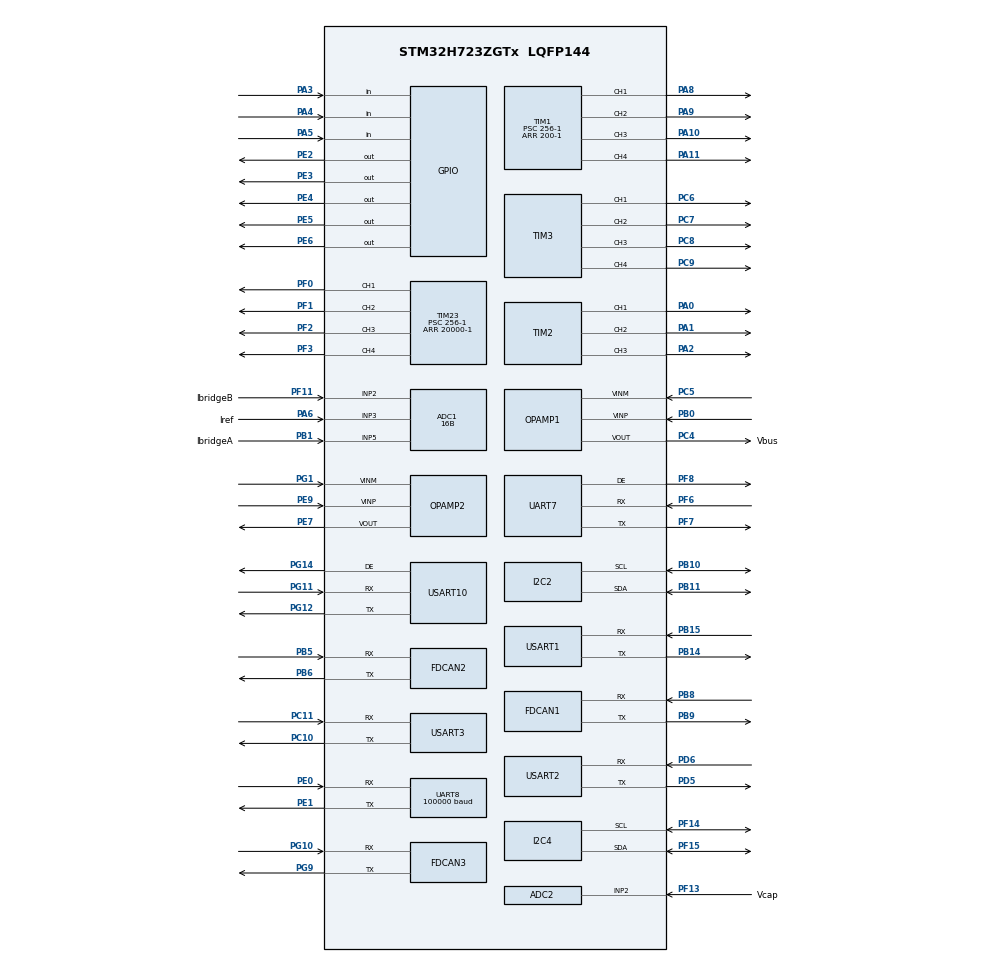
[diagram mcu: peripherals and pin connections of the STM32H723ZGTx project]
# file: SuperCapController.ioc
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ADC1.Channel-0\#ChannelRegularConversion=ADC_CHANNEL_4
ADC1.Channel-1\#ChannelRegularConversion=ADC_CHANNEL_2
ADC1.Channel-2\#ChannelRegularConversion=ADC_CHANNEL_3
ADC1.Channel-3\#ChannelRegularConversion=ADC_CHANNEL_5
ADC1.ClockPrescaler=ADC_CLOCK_ASYNC_DIV128
ADC1.ContinuousConvMode=ENABLE
ADC1.ConversionDataManagement=ADC_CONVERSIONDATA_DMA_CIRCULAR
ADC1.EOCSelection=ADC_EOC_SINGLE_CONV
ADC1.NbrOfConversion=4
ADC1.NbrOfConversionFlag=1
ADC1.OffsetNumber-0\#ChannelRegularConversion=ADC_OFFSET_NONE
ADC1.OffsetNumber-1\#ChannelRegularConversion=ADC_OFFSET_NONE
ADC1.OffsetNumber-2\#ChannelRegularConversion=ADC_OFFSET_NONE
ADC1.OffsetNumber-3\#ChannelRegularConversion=ADC_OFFSET_NONE
ADC1.OffsetSignedSaturation-0\#ChannelRegularConversion=DISABLE
ADC1.OffsetSignedSaturation-1\#ChannelRegularConversion=DISABLE
ADC1.OffsetSignedSaturation-2\#ChannelRegularConversion=DISABLE
ADC1.OffsetSignedSaturation-3\#ChannelRegularConversion=DISABLE
ADC1.Rank-0\#ChannelRegularConversion=1
ADC1.Rank-1\#ChannelRegularConversion=2
ADC1.Rank-2\#ChannelRegularConversion=3
ADC1.Rank-3\#ChannelRegularConversion=4
ADC1.Resolution=ADC_RESOLUTION_16B
ADC1.SamplingTime-0\#ChannelRegularConversion=ADC_SAMPLETIME_32CYCLES_5
ADC1.SamplingTime-1\#ChannelRegularConversion=ADC_SAMPLETIME_32CYCLES_5
ADC1.SamplingTime-2\#ChannelRegularConversion=ADC_SAMPLETIME_32CYCLES_5
ADC1.SamplingTime-3\#ChannelRegularConversion=ADC_SAMPLETIME_32CYCLES_5
ADC1.master=1
ADC2.Channel-2\#ChannelRegularConversion=ADC_CHANNEL_2
ADC2.Channel-3\#ChannelRegularConversion=ADC_CHANNEL_2
ADC2.ClockPrescaler=ADC_CLOCK_ASYNC_DIV128
ADC2.ContinuousConvMode=ENABLE
ADC2.ConversionDataManagement=ADC_CONVERSIONDATA_DMA_CIRCULAR
ADC2.NbrOfConversion=2
ADC2.NbrOfConversionFlag=1
ADC2.OffsetNumber-2\#ChannelRegularConversion=ADC_OFFSET_NONE
ADC2.OffsetNumber-3\#ChannelRegularConversion=ADC_OFFSET_NONE
ADC2.OffsetSignedSaturation-2\#ChannelRegularConversion=DISABLE
ADC2.OffsetSignedSaturation-3\#ChannelRegularConversion=DISABLE
ADC2.Rank-2\#ChannelRegularConversion=1
ADC2.Rank-3\#ChannelRegularConversion=2
ADC2.Resolution=ADC_RESOLUTION_16B
ADC2.SamplingTime-2\#ChannelRegularConversion=ADC_SAMPLETIME_16CYCLES_5
ADC2.SamplingTime-3\#ChannelRegularConversion=ADC_SAMPLETIME_16CYCLES_5
CORTEX_M7.default_mode_Activation=0
Dma.ADC1.6.Direction=DMA_PERIPH_TO_MEMORY
Dma.ADC1.6.EventEnable=DISABLE
Dma.ADC1.6.FIFOMode=DMA_FIFOMODE_DISABLE
Dma.ADC1.6.Instance=DMA1_Stream6
Dma.ADC1.6.MemDataAlignment=DMA_MDATAALIGN_HALFWORD
Dma.ADC1.6.MemInc=DMA_MINC_ENABLE
Dma.ADC1.6.Mode=DMA_CIRCULAR
Dma.ADC1.6.PeriphDataAlignment=DMA_PDATAALIGN_HALFWORD
Dma.ADC1.6.PeriphInc=DMA_PINC_DISABLE
Dma.ADC1.6.Polarity=HAL_DMAMUX_REQ_GEN_RISING
Dma.ADC1.6.Priority=DMA_PRIORITY_LOW
Dma.ADC1.6.RequestNumber=1
Dma.ADC1.6.SignalID=NONE
Dma.ADC1.6.SyncEnable=DISABLE
Dma.ADC1.6.SyncPolarity=HAL_DMAMUX_SYNC_NO_EVENT
Dma.ADC1.6.SyncRequestNumber=1
Dma.ADC1.6.SyncSignalID=NONE
Dma.ADC2.7.Direction=DMA_PERIPH_TO_MEMORY
Dma.ADC2.7.EventEnable=DISABLE
Dma.ADC2.7.FIFOMode=DMA_FIFOMODE_DISABLE
Dma.ADC2.7.Instance=DMA1_Stream7
Dma.ADC2.7.MemDataAlignment=DMA_MDATAALIGN_HALFWORD
Dma.ADC2.7.MemInc=DMA_MINC_ENABLE
Dma.ADC2.7.Mode=DMA_CIRCULAR
Dma.ADC2.7.PeriphDataAlignment=DMA_PDATAALIGN_HALFWORD
Dma.ADC2.7.PeriphInc=DMA_PINC_DISABLE
Dma.ADC2.7.Polarity=HAL_DMAMUX_REQ_GEN_RISING
Dma.ADC2.7.Priority=DMA_PRIORITY_LOW
Dma.ADC2.7.RequestNumber=1
Dma.ADC2.7.SignalID=NONE
Dma.ADC2.7.SyncEnable=DISABLE
Dma.ADC2.7.SyncPolarity=HAL_DMAMUX_SYNC_NO_EVENT
Dma.ADC2.7.SyncRequestNumber=1
Dma.ADC2.7.SyncSignalID=NONE
Dma.Request0=USART3_TX
Dma.Request1=USART2_TX
Dma.Request2=USART1_TX
Dma.Request3=USART1_RX
Dma.Request4=USART2_RX
Dma.Request5=USART3_RX
Dma.Request6=ADC1
Dma.Request7=ADC2
Dma.Request8=UART8_RX
Dma.UART8_RX.8.Direction=DMA_PERIPH_TO_MEMORY
Dma.UART8_RX.8.EventEnable=DISABLE
Dma.UART8_RX.8.FIFOMode=DMA_FIFOMODE_DISABLE
Dma.UART8_RX.8.Instance=DMA2_Stream0
Dma.UART8_RX.8.MemDataAlignment=DMA_MDATAALIGN_BYTE
Dma.UART8_RX.8.MemInc=DMA_MINC_ENABLE
Dma.UART8_RX.8.Mode=DMA_NORMAL
Dma.UART8_RX.8.PeriphDataAlignment=DMA_PDATAALIGN_BYTE
Dma.UART8_RX.8.PeriphInc=DMA_PINC_DISABLE
Dma.UART8_RX.8.Polarity=HAL_DMAMUX_REQ_GEN_RISING
Dma.UART8_RX.8.Priority=DMA_PRIORITY_VERY_HIGH
Dma.UART8_RX.8.RequestNumber=1
Dma.UART8_RX.8.SignalID=NONE
Dma.UART8_RX.8.SyncEnable=DISABLE
Dma.UART8_RX.8.SyncPolarity=HAL_DMAMUX_SYNC_NO_EVENT
Dma.UART8_RX.8.SyncRequestNumber=1
Dma.UART8_RX.8.SyncSignalID=NONE
Dma.USART1_RX.3.Direction=DMA_PERIPH_TO_MEMORY
Dma.USART1_RX.3.EventEnable=DISABLE
Dma.USART1_RX.3.FIFOMode=DMA_FIFOMODE_DISABLE
Dma.USART1_RX.3.Instance=DMA1_Stream3
Dma.USART1_RX.3.MemDataAlignment=DMA_MDATAALIGN_BYTE
Dma.USART1_RX.3.MemInc=DMA_MINC_ENABLE
Dma.USART1_RX.3.Mode=DMA_NORMAL
Dma.USART1_RX.3.PeriphDataAlignment=DMA_PDATAALIGN_BYTE
Dma.USART1_RX.3.PeriphInc=DMA_PINC_DISABLE
Dma.USART1_RX.3.Polarity=HAL_DMAMUX_REQ_GEN_RISING
Dma.USART1_RX.3.Priority=DMA_PRIORITY_VERY_HIGH
Dma.USART1_RX.3.RequestNumber=1
Dma.USART1_RX.3.SignalID=NONE
Dma.USART1_RX.3.SyncEnable=DISABLE
Dma.USART1_RX.3.SyncPolarity=HAL_DMAMUX_SYNC_NO_EVENT
Dma.USART1_RX.3.SyncRequestNumber=1
Dma.USART1_RX.3.SyncSignalID=NONE
Dma.USART1_TX.2.Direction=DMA_MEMORY_TO_PERIPH
Dma.USART1_TX.2.EventEnable=DISABLE
Dma.USART1_TX.2.FIFOMode=DMA_FIFOMODE_DISABLE
Dma.USART1_TX.2.Instance=DMA1_Stream2
Dma.USART1_TX.2.MemDataAlignment=DMA_MDATAALIGN_BYTE
Dma.USART1_TX.2.MemInc=DMA_MINC_ENABLE
Dma.USART1_TX.2.Mode=DMA_NORMAL
Dma.USART1_TX.2.PeriphDataAlignment=DMA_PDATAALIGN_BYTE
Dma.USART1_TX.2.PeriphInc=DMA_PINC_DISABLE
Dma.USART1_TX.2.Polarity=HAL_DMAMUX_REQ_GEN_RISING
Dma.USART1_TX.2.Priority=DMA_PRIORITY_VERY_HIGH
Dma.USART1_TX.2.RequestNumber=1
Dma.USART1_TX.2.SignalID=NONE
Dma.USART1_TX.2.SyncEnable=DISABLE
Dma.USART1_TX.2.SyncPolarity=HAL_DMAMUX_SYNC_NO_EVENT
Dma.USART1_TX.2.SyncRequestNumber=1
Dma.USART1_TX.2.SyncSignalID=NONE
Dma.USART2_RX.4.Direction=DMA_PERIPH_TO_MEMORY
Dma.USART2_RX.4.EventEnable=DISABLE
Dma.USART2_RX.4.FIFOMode=DMA_FIFOMODE_DISABLE
Dma.USART2_RX.4.Instance=DMA1_Stream4
Dma.USART2_RX.4.MemDataAlignment=DMA_MDATAALIGN_BYTE
Dma.USART2_RX.4.MemInc=DMA_MINC_ENABLE
Dma.USART2_RX.4.Mode=DMA_NORMAL
Dma.USART2_RX.4.PeriphDataAlignment=DMA_PDATAALIGN_BYTE
Dma.USART2_RX.4.PeriphInc=DMA_PINC_DISABLE
Dma.USART2_RX.4.Polarity=HAL_DMAMUX_REQ_GEN_RISING
Dma.USART2_RX.4.Priority=DMA_PRIORITY_VERY_HIGH
Dma.USART2_RX.4.RequestNumber=1
Dma.USART2_RX.4.SignalID=NONE
Dma.USART2_RX.4.SyncEnable=DISABLE
Dma.USART2_RX.4.SyncPolarity=HAL_DMAMUX_SYNC_NO_EVENT
Dma.USART2_RX.4.SyncRequestNumber=1
Dma.USART2_RX.4.SyncSignalID=NONE
Dma.USART2_TX.1.Direction=DMA_MEMORY_TO_PERIPH
Dma.USART2_TX.1.EventEnable=DISABLE
Dma.USART2_TX.1.FIFOMode=DMA_FIFOMODE_DISABLE
Dma.USART2_TX.1.Instance=DMA1_Stream1
Dma.USART2_TX.1.MemDataAlignment=DMA_MDATAALIGN_BYTE
Dma.USART2_TX.1.MemInc=DMA_MINC_ENABLE
Dma.USART2_TX.1.Mode=DMA_NORMAL
Dma.USART2_TX.1.PeriphDataAlignment=DMA_PDATAALIGN_BYTE
Dma.USART2_TX.1.PeriphInc=DMA_PINC_DISABLE
Dma.USART2_TX.1.Polarity=HAL_DMAMUX_REQ_GEN_RISING
Dma.USART2_TX.1.Priority=DMA_PRIORITY_VERY_HIGH
Dma.USART2_TX.1.RequestNumber=1
Dma.USART2_TX.1.SignalID=NONE
Dma.USART2_TX.1.SyncEnable=DISABLE
Dma.USART2_TX.1.SyncPolarity=HAL_DMAMUX_SYNC_NO_EVENT
Dma.USART2_TX.1.SyncRequestNumber=1
Dma.USART2_TX.1.SyncSignalID=NONE
Dma.USART3_RX.5.Direction=DMA_PERIPH_TO_MEMORY
Dma.USART3_RX.5.EventEnable=DISABLE
Dma.USART3_RX.5.FIFOMode=DMA_FIFOMODE_DISABLE
Dma.USART3_RX.5.Instance=DMA1_Stream5
Dma.USART3_RX.5.MemDataAlignment=DMA_MDATAALIGN_BYTE
Dma.USART3_RX.5.MemInc=DMA_MINC_ENABLE
Dma.USART3_RX.5.Mode=DMA_NORMAL
Dma.USART3_RX.5.PeriphDataAlignment=DMA_PDATAALIGN_BYTE
Dma.USART3_RX.5.PeriphInc=DMA_PINC_DISABLE
Dma.USART3_RX.5.Polarity=HAL_DMAMUX_REQ_GEN_RISING
Dma.USART3_RX.5.Priority=DMA_PRIORITY_VERY_HIGH
Dma.USART3_RX.5.RequestNumber=1
Dma.USART3_RX.5.SignalID=NONE
Dma.USART3_RX.5.SyncEnable=DISABLE
Dma.USART3_RX.5.SyncPolarity=HAL_DMAMUX_SYNC_NO_EVENT
Dma.USART3_RX.5.SyncRequestNumber=1
Dma.USART3_RX.5.SyncSignalID=NONE
Dma.USART3_TX.0.Direction=DMA_MEMORY_TO_PERIPH
Dma.USART3_TX.0.EventEnable=DISABLE
Dma.USART3_TX.0.FIFOMode=DMA_FIFOMODE_DISABLE
Dma.USART3_TX.0.Instance=DMA1_Stream0
Dma.USART3_TX.0.MemDataAlignment=DMA_MDATAALIGN_BYTE
Dma.USART3_TX.0.MemInc=DMA_MINC_ENABLE
Dma.USART3_TX.0.Mode=DMA_NORMAL
Dma.USART3_TX.0.PeriphDataAlignment=DMA_PDATAALIGN_BYTE
Dma.USART3_TX.0.PeriphInc=DMA_PINC_DISABLE
Dma.USART3_TX.0.Polarity=HAL_DMAMUX_REQ_GEN_RISING
Dma.USART3_TX.0.Priority=DMA_PRIORITY_VERY_HIGH
Dma.USART3_TX.0.RequestNumber=1
Dma.USART3_TX.0.SignalID=NONE
Dma.USART3_TX.0.SyncEnable=DISABLE
Dma.USART3_TX.0.SyncPolarity=HAL_DMAMUX_SYNC_NO_EVENT
Dma.USART3_TX.0.SyncRequestNumber=1
Dma.USART3_TX.0.SyncSignalID=NONE
FDCAN1.CalculateBaudRateNominal=1000000
FDCAN1.CalculateTimeBitNominal=1000
FDCAN1.CalculateTimeQuantumNominal=47.61904761904762
FDCAN1.DataPrescaler=6
FDCAN1.DataSyncJumpWidth=5
FDCAN1.DataTimeSeg1=15
FDCAN1.DataTimeSeg2=5
FDCAN1.ExtFiltersNbr=0
FDCAN1.Mode=FDCAN_MODE_NORMAL
FDCAN1.NominalPrescaler=6
FDCAN1.NominalSyncJumpWidth=5
FDCAN1.NominalTimeSeg1=15
FDCAN1.NominalTimeSeg2=5
FDCAN1.RxBuffersNbr=4
FDCAN1.RxFifo0ElmtsNbr=4
FDCAN1.RxFifo1ElmtsNbr=4
FDCAN1.StdFiltersNbr=1
FDCAN1.TxBuffersNbr=8
FDCAN1.TxEventsNbr=4
FDCAN1.TxFifoQueueElmtsNbr=8
FDCAN2.CalculateBaudRateNominal=1000000
FDCAN2.CalculateTimeBitNominal=1000
FDCAN2.CalculateTimeQuantumNominal=47.61904761904762
FDCAN2.DataPrescaler=6
FDCAN2.DataSyncJumpWidth=5
FDCAN2.DataTimeSeg1=15
FDCAN2.DataTimeSeg2=5
FDCAN2.MessageRAMOffset=0x406
FDCAN2.NominalPrescaler=6
FDCAN2.NominalSyncJumpWidth=5
FDCAN2.NominalTimeSeg1=15
FDCAN2.NominalTimeSeg2=5
FDCAN2.RxBuffersNbr=4
FDCAN2.RxFifo0ElmtsNbr=4
FDCAN2.RxFifo1ElmtsNbr=4
FDCAN2.StdFiltersNbr=1
FDCAN2.TxBuffersNbr=8
FDCAN2.TxEventsNbr=4
FDCAN2.TxFifoQueueElmtsNbr=8
FDCAN3.CalculateBaudRateNominal=1000000
FDCAN3.CalculateTimeBitNominal=1000
FDCAN3.CalculateTimeQuantumNominal=47.61904761904762
FDCAN3.DataPrescaler=6
FDCAN3.DataSyncJumpWidth=5
FDCAN3.DataTimeSeg1=15
FDCAN3.DataTimeSeg2=5
FDCAN3.MessageRAMOffset=0x812
FDCAN3.NominalPrescaler=6
FDCAN3.NominalSyncJumpWidth=5
FDCAN3.NominalTimeSeg1=15
FDCAN3.NominalTimeSeg2=5
FDCAN3.RxBuffersNbr=4
FDCAN3.RxFifo0ElmtsNbr=4
FDCAN3.RxFifo1ElmtsNbr=4
FDCAN3.StdFiltersNbr=1
FDCAN3.TxBuffersNbr=8
FDCAN3.TxEventsNbr=4
FDCAN3.TxFifoQueueElmtsNbr=8
FREERTOS.Tasks01=defaultTask,0,1024,StartDefaultTask,Default,NULL,Dynamic,NULL,NULL
I2C2.Timing=0x20A0C4DF
I2C4.Timing=0x20A0C4DF
Mcu.Family=STM32H7
Mcu.Name=STM32H723ZGTx
Mcu.Package=LQFP144
NVIC.DMA1_Stream0_IRQn=true\:5\:0\:false\:false\:true\:true\:false\:true\:true
NVIC.DMA1_Stream1_IRQn=true\:5\:0\:false\:false\:true\:true\:false\:true\:true
NVIC.DMA1_Stream2_IRQn=true\:5\:0\:false\:false\:true\:true\:false\:true\:true
NVIC.DMA1_Stream3_IRQn=true\:5\:0\:false\:false\:true\:true\:false\:true\:true
NVIC.DMA1_Stream4_IRQn=true\:5\:0\:false\:false\:true\:true\:false\:true\:true
NVIC.DMA1_Stream5_IRQn=true\:5\:0\:false\:false\:true\:true\:false\:true\:true
NVIC.DMA1_Stream6_IRQn=true\:5\:0\:false\:false\:true\:true\:false\:true\:true
NVIC.DMA1_Stream7_IRQn=true\:5\:0\:false\:false\:true\:true\:false\:true\:true
NVIC.DMA2_Stream0_IRQn=true\:5\:0\:false\:false\:true\:true\:false\:true\:true
NVIC.FDCAN1_IT0_IRQn=true\:5\:0\:false\:false\:true\:true\:true\:true\:true
NVIC.FDCAN1_IT1_IRQn=true\:5\:0\:false\:false\:true\:true\:true\:true\:true
NVIC.FDCAN2_IT0_IRQn=true\:5\:0\:false\:false\:true\:true\:true\:true\:true
NVIC.FDCAN2_IT1_IRQn=true\:5\:0\:false\:false\:true\:true\:true\:true\:true
NVIC.FDCAN3_IT0_IRQn=true\:5\:0\:false\:false\:true\:true\:true\:true\:true
NVIC.FDCAN3_IT1_IRQn=true\:5\:0\:false\:false\:true\:true\:true\:true\:true
NVIC.PriorityGroup=NVIC_PRIORITYGROUP_4
NVIC.UART8_IRQn=true\:5\:0\:false\:false\:true\:true\:true\:true\:true
NVIC.USART1_IRQn=true\:5\:0\:false\:false\:true\:true\:true\:true\:true
NVIC.USART2_IRQn=true\:5\:0\:false\:false\:true\:true\:true\:true\:true
NVIC.USART3_IRQn=true\:5\:0\:false\:false\:true\:true\:true\:true\:true
OPAMP1.PowerMode=OPAMP_POWERMODE_NORMAL
OPAMP2.PowerMode=OPAMP_POWERMODE_NORMAL
PA0.Signal=S_TIM2_CH1_ETR
PA1.Signal=S_TIM2_CH2
PA10.Signal=S_TIM1_CH3
PA11.Signal=S_TIM1_CH4
PA13(JTMS/SWDIO).Mode=Serial_Wire
PA13(JTMS/SWDIO).Signal=DEBUG_JTMS-SWDIO
PA14(JTCK/SWCLK).Mode=Serial_Wire
PA14(JTCK/SWCLK).Signal=DEBUG_JTCK-SWCLK
PA2.Signal=S_TIM2_CH3
PA3.Signal=GPIO_Input
PA4.Signal=GPIO_Input
PA5.Signal=GPIO_Input
PA6.GPIO_Label=Iref
PA6.Signal=ADCx_INP3
PA8.Signal=S_TIM1_CH1
PA9.Signal=S_TIM1_CH2
PB0.Mode=Standalone
PB0.Signal=OPAMP1_VINP
PB1.GPIO_Label=IbridgeA
PB1.Signal=ADCx_INP5
PB10.Mode=I2C
PB10.Signal=I2C2_SCL
PB11.Mode=I2C
PB11.Signal=I2C2_SDA
PB14.Mode=Asynchronous
PB14.Signal=USART1_TX
PB15.Mode=Asynchronous
PB15.Signal=USART1_RX
PB5.Mode=FDCAN_Activate
PB5.Signal=FDCAN2_RX
PB6.Mode=FDCAN_Activate
PB6.Signal=FDCAN2_TX
PB8.Mode=FDCAN_Activate
PB8.Signal=FDCAN1_RX
PB9.Mode=FDCAN_Activate
PB9.Signal=FDCAN1_TX
PC10.Mode=Asynchronous
PC10.Signal=USART3_TX
PC11.Mode=Asynchronous
PC11.Signal=USART3_RX
PC4.GPIO_Label=Vbus
PC4.Signal=SharedAnalog_PC4
PC5.Mode=Standalone
PC5.Signal=OPAMP1_VINM
PC6.Signal=S_TIM3_CH1
PC7.Signal=S_TIM3_CH2
PC8.Signal=S_TIM3_CH3
PC9.Signal=S_TIM3_CH4
PD5.Mode=Asynchronous
PD5.Signal=USART2_TX
PD6.Mode=Asynchronous
PD6.Signal=USART2_RX
PE0.Mode=Asynchronous
PE0.Signal=UART8_RX
PE1.Mode=Asynchronous
PE1.Signal=UART8_TX
PE2.GPIO_PuPd=GPIO_NOPULL
PE2.GPIO_Speed=GPIO_SPEED_FREQ_MEDIUM
PE2.Signal=GPIO_Output
PE3.GPIO_ModeDefaultOutputPP=GPIO_MODE_OUTPUT_PP
PE3.GPIO_PuPd=GPIO_NOPULL
PE3.GPIO_Speed=GPIO_SPEED_FREQ_MEDIUM
PE3.PinState=GPIO_PIN_RESET
PE3.Signal=GPIO_Output
PE4.GPIO_ModeDefaultOutputPP=GPIO_MODE_OUTPUT_PP
PE4.GPIO_PuPd=GPIO_NOPULL
PE4.GPIO_Speed=GPIO_SPEED_FREQ_MEDIUM
PE4.Signal=GPIO_Output
PE5.GPIO_ModeDefaultOutputPP=GPIO_MODE_OUTPUT_PP
PE5.GPIO_PuPd=GPIO_NOPULL
PE5.GPIO_Speed=GPIO_SPEED_FREQ_MEDIUM
PE5.Signal=GPIO_Output
PE6.GPIO_PuPd=GPIO_NOPULL
PE6.GPIO_Speed=GPIO_SPEED_FREQ_MEDIUM
PE6.Signal=GPIO_Output
PE7.Mode=Standalone
PE7.Signal=OPAMP2_VOUT
PE9.Mode=Standalone
PE9.Signal=OPAMP2_VINP
PF0.Mode=PWM Generation1 CH1
PF0.Signal=TIM23_CH1
PF1.Signal=S_TIM23_CH2
PF11.GPIO_Label=IbridgeB
PF11.Mode=IN2-Single-Ended
PF11.Signal=ADC1_INP2
PF13.GPIO_Label=Vcap
PF13.Mode=IN2-Single-Ended
PF13.Signal=ADC2_INP2
PF14.Mode=I2C
PF14.Signal=I2C4_SCL
PF15.Mode=I2C
PF15.Signal=I2C4_SDA
PF2.Signal=S_TIM23_CH3
PF3.Signal=S_TIM23_CH4
PF6.Mode=Asynchronous
PF6.Signal=UART7_RX
PF7.Mode=Asynchronous
PF7.Signal=UART7_TX
PF8.Mode=Hardware Flow Control (RS485)
PF8.Signal=UART7_DE
PG1.Mode=Standalone
PG1.Signal=OPAMP2_VINM
PG10.Mode=FDCAN_Activate
PG10.Signal=FDCAN3_RX
PG11.Mode=Asynchronous
PG11.Signal=USART10_RX
PG12.Mode=Asynchronous
PG12.Signal=USART10_TX
PG14.Mode=Hardware Flow Control (RS485)
PG14.Signal=USART10_DE
PG9.Mode=FDCAN_Activate
PG9.Signal=FDCAN3_TX
PH0-OSC_IN.Mode=HSE-External-Oscillator
PH0-OSC_IN.Signal=RCC_OSC_IN
PH1-OSC_OUT.Mode=HSE-External-Oscillator
PH1-OSC_OUT.Signal=RCC_OSC_OUT
ProjectManager.HeapSize=0x200
ProjectManager.StackSize=0x400
ProjectManager.TargetToolchain=STM32CubeIDE
RCC.ADCFreq_Value=126000000
RCC.APB1Freq_Value=128000000
RCC.APB2Freq_Value=128000000
RCC.APB3Freq_Value=128000000
RCC.APB4Freq_Value=128000000
RCC.CortexFreq_Value=256000000
RCC.D1PPRE=RCC_APB3_DIV2
RCC.D2PPRE1=RCC_APB1_DIV2
RCC.D2PPRE2=RCC_APB2_DIV2
RCC.D3PPRE=RCC_APB4_DIV2
RCC.DIVM1=1
RCC.DIVM2=1
RCC.DIVN1=64
RCC.DIVN2=21
RCC.DIVP1=3
RCC.DIVQ1=6
RCC.FDCANCLockSelection=RCC_FDCANCLKSOURCE_PLL2
RCC.HCLKFreq_Value=256000000
RCC.HSE_VALUE=12000000
RCC.PLL2FRACN=0
RCC.PLL2_VCI_Range-AdvancedSettings=RCC_PLL2VCIRANGE_0
RCC.PLL2_VCO_SEL-AdvancedSettings=RCC_PLL2VCOMEDIUM
RCC.PLL3FRACN=0
RCC.PLLFRACN=0
RCC.PLLSourceVirtual=RCC_PLLSOURCE_HSE
RCC.SYSCLKFreq_VALUE=256000000
RCC.SYSCLKSource=RCC_SYSCLKSOURCE_PLLCLK
RCC.USBFreq_Value=128000000
SH.ADCx_INP3.0=ADC1_INP3,IN3-Single-Ended
SH.ADCx_INP5.0=ADC1_INP5,IN5-Single-Ended
SH.S_TIM1_CH1.0=TIM1_CH1,PWM Generation1 CH1
SH.S_TIM1_CH2.0=TIM1_CH2,PWM Generation2 CH2
SH.S_TIM1_CH3.0=TIM1_CH3,PWM Generation3 CH3
SH.S_TIM1_CH4.0=TIM1_CH4,PWM Generation4 CH4
SH.S_TIM23_CH2.0=TIM23_CH2,PWM Generation2 CH2
SH.S_TIM23_CH3.0=TIM23_CH3,PWM Generation3 CH3
SH.S_TIM23_CH4.0=TIM23_CH4,PWM Generation4 CH4
SH.S_TIM2_CH1_ETR.0=TIM2_CH1,PWM Generation1 CH1
SH.S_TIM2_CH2.0=TIM2_CH2,PWM Generation2 CH2
SH.S_TIM2_CH3.0=TIM2_CH3,PWM Generation3 CH3
SH.S_TIM3_CH1.0=TIM3_CH1,PWM Generation1 CH1
SH.S_TIM3_CH2.0=TIM3_CH2,PWM Generation2 CH2
SH.S_TIM3_CH3.0=TIM3_CH3,PWM Generation3 CH3
SH.S_TIM3_CH4.0=TIM3_CH4,PWM Generation4 CH4
SH.SharedAnalog_PC4.0=ADC1_INP4
SH.SharedAnalog_PC4.1=OPAMP1_VOUT,Standalone
TIM1.AutoReloadPreload=TIM_AUTORELOAD_PRELOAD_ENABLE
TIM1.Channel-PWM\ Generation1\ CH1=TIM_CHANNEL_1
TIM1.Channel-PWM\ Generation2\ CH2=TIM_CHANNEL_2
TIM1.Channel-PWM\ Generation3\ CH3=TIM_CHANNEL_3
TIM1.Channel-PWM\ Generation4\ CH4=TIM_CHANNEL_4
TIM1.Period=200-1
TIM1.Prescaler=256-1
TIM1.Pulse-PWM\ Generation1\ CH1=100-1
TIM1.Pulse-PWM\ Generation2\ CH2=100-1
TIM1.Pulse-PWM\ Generation3\ CH3=100-1
TIM1.Pulse-PWM\ Generation4\ CH4=100-1
TIM2.Channel-PWM\ Generation1\ CH1=TIM_CHANNEL_1
TIM2.Channel-PWM\ Generation2\ CH2=TIM_CHANNEL_2
TIM2.Channel-PWM\ Generation3\ CH3=TIM_CHANNEL_3
TIM23.AutoReloadPreload=TIM_AUTORELOAD_PRELOAD_ENABLE
TIM23.Channel-PWM\ Generation1\ CH1=TIM_CHANNEL_1
TIM23.Channel-PWM\ Generation2\ CH2=TIM_CHANNEL_2
TIM23.Channel-PWM\ Generation3\ CH3=TIM_CHANNEL_3
TIM23.Channel-PWM\ Generation4\ CH4=TIM_CHANNEL_4
TIM23.Period=20000-1
TIM23.Prescaler=256-1
TIM23.Pulse-PWM\ Generation1\ CH1=1000-1
TIM23.Pulse-PWM\ Generation2\ CH2=1000-1
TIM23.Pulse-PWM\ Generation3\ CH3=1000-1
TIM23.Pulse-PWM\ Generation4\ CH4=1000-1
TIM3.Channel-PWM\ Generation1\ CH1=TIM_CHANNEL_1
TIM3.Channel-PWM\ Generation2\ CH2=TIM_CHANNEL_2
TIM3.Channel-PWM\ Generation3\ CH3=TIM_CHANNEL_3
TIM3.Channel-PWM\ Generation4\ CH4=TIM_CHANNEL_4
UART8.BaudRate=100000
UART8.Parity=PARITY_EVEN
UART8.StopBits=UART_STOPBITS_1
UART8.WordLength=WORDLENGTH_8B
USART1.VirtualMode-Asynchronous=VM_ASYNC
USART10.VirtualMode-Asynchronous=VM_ASYNC
USART10.VirtualMode-Hardware\ Flow\ Control\ (RS485)=VM_ASYNC
USART2.VirtualMode-Asynchronous=VM_ASYNC
USART3.VirtualMode-Asynchronous=VM_ASYNC
VP_ADC1_OPAMP1_OUT.Mode=IN4-OPAMP1-Single-Ended
VP_FREERTOS_VS_CMSIS_V1.Mode=CMSIS_V1
VP_MEMORYMAP_VS_MEMORYMAP.Mode=CurAppReg
VP_TIM1_VS_ClockSourceINT.Mode=Internal
VP_TIM23_VS_ClockSourceINT.Mode=Internal
board=custom

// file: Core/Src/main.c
/* USER CODE BEGIN Header */
/**
  ******************************************************************************
  * @file           : main.c
  * @brief          : Main program body
  ******************************************************************************
  * @attention
  *
  * Copyright (c) 2025 STMicroelectronics.
  * All rights reserved.
  *
  * This software is licensed under terms that can be found in the LICENSE file
  * in the root directory of this software component.
  * If no LICENSE file comes with this software, it is provided AS-IS.
  *
  ******************************************************************************
  */
/* USER CODE END Header */
#include "main.h"
#include "cmsis_os.h"

/* USER CODE BEGIN Includes */
#include "stdio.h"
#include "stdarg.h"
#include "string.h"
#include "UART.h"
#include "CAN_FD.h"
#include "cybergear.h"
#include "remote_control.h"
#include "stdlib.h"

/* USER CODE END Includes */

ADC_HandleTypeDef hadc1;
ADC_HandleTypeDef hadc2;
DMA_HandleTypeDef hdma_adc1;
DMA_HandleTypeDef hdma_adc2;

FDCAN_HandleTypeDef hfdcan1;
FDCAN_HandleTypeDef hfdcan2;
FDCAN_HandleTypeDef hfdcan3;

I2C_HandleTypeDef hi2c2;
I2C_HandleTypeDef hi2c4;

OPAMP_HandleTypeDef hopamp1;
OPAMP_HandleTypeDef hopamp2;

TIM_HandleTypeDef htim1;
TIM_HandleTypeDef htim2;
TIM_HandleTypeDef htim3;
TIM_HandleTypeDef htim23;

UART_HandleTypeDef huart7;
UART_HandleTypeDef huart8;
UART_HandleTypeDef huart1;
UART_HandleTypeDef huart2;
UART_HandleTypeDef huart3;
UART_HandleTypeDef huart10;
DMA_HandleTypeDef hdma_uart8_rx;
DMA_HandleTypeDef hdma_usart1_tx;
DMA_HandleTypeDef hdma_usart1_rx;
DMA_HandleTypeDef hdma_usart2_tx;
DMA_HandleTypeDef hdma_usart2_rx;
DMA_HandleTypeDef hdma_usart3_tx;
DMA_HandleTypeDef hdma_usart3_rx;

osThreadId defaultTaskHandle;
/* USER CODE BEGIN PV */
FDCAN_HandleTypeDef hfdcan1;
FDCAN_HandleTypeDef hfdcan2;
FDCAN_HandleTypeDef hfdcan3;

PID_preset_t chassisPreset = {3.6, 0, 0};  //0.8f, 0.025f, 0.95f   {1.6, 0.045, 0.10}; 32 0.4
PID_preset_t yawPresetCurrentRPM = {46, 10.0, 16.4};
PID_preset_t yawPresetVoltageRPM = {300, 0, 0};
PID_preset_t yawPresetCurrentPosition = {12, 1, 0.0};
PID_preset_t yawPresetVoltagePosition = {36, 0.3, 0.0};
PID_preset_t pitchPresetVoltagePosition = {70.0, 0.0, 421.0};
PID_preset_t indexerPreset = {1.1f, 0.02f, -2.4f};
PID_preset_t shooterPreset = {1.20f, 0.12f, 1.60f};
PID_preset_t powerPreset = {0, 0.000000000001, 0};
PID_preset_t flywheel = {12, 0, 0};
PID_preset_t customPreset = {0, 0, 0};

RC_ctrl_t local_rc_ctrl;

const int16_t maxValAllowed = 800;
/* USER CODE END PV */

void SystemClock_Config(void);
void PeriphCommonClock_Config(void);
static void MX_GPIO_Init(void);
static void MX_DMA_Init(void);
static void MX_ADC1_Init(void);
static void MX_ADC2_Init(void);
static void MX_FDCAN1_Init(void);
static void MX_FDCAN2_Init(void);
static void MX_FDCAN3_Init(void);
static void MX_I2C2_Init(void);
static void MX_I2C4_Init(void);
static void MX_OPAMP1_Init(void);
static void MX_OPAMP2_Init(void);
static void MX_TIM1_Init(void);
static void MX_TIM2_Init(void);
static void MX_TIM3_Init(void);
static void MX_TIM23_Init(void);
static void MX_UART7_Init(void);
static void MX_USART1_UART_Init(void);
static void MX_USART2_UART_Init(void);
static void MX_USART3_UART_Init(void);
static void MX_USART10_UART_Init(void);
static void MX_UART8_Init(void);
void StartDefaultTask(void const * argument);

int main(void)
{

  /* MCU Configuration--------------------------------------------------------*/

  /* Reset of all peripherals, Initializes the Flash interface and the Systick. */
  HAL_Init();

  /* Configure the system clock */
  SystemClock_Config();

  /* Configure the peripherals common clocks */
  PeriphCommonClock_Config();

  /* Initialize all configured peripherals */
  MX_GPIO_Init();
  MX_DMA_Init();
  MX_ADC1_Init();
  MX_ADC2_Init();
  MX_FDCAN1_Init();
  MX_FDCAN2_Init();
  MX_FDCAN3_Init();
  MX_I2C2_Init();
  MX_I2C4_Init();
  MX_OPAMP1_Init();
  MX_OPAMP2_Init();
  MX_TIM1_Init();
  MX_TIM2_Init();
  MX_TIM3_Init();
  MX_TIM23_Init();
  MX_UART7_Init();
  MX_USART1_UART_Init();
  MX_USART2_UART_Init();
  MX_USART3_UART_Init();
  MX_USART10_UART_Init();
  MX_UART8_Init();
  /* USER CODE BEGIN 2 */
  HAL_TIM_Base_Start(&htim1);
  HAL_TIM_PWM_Start(&htim1, TIM_CHANNEL_1);
  HAL_TIM_PWM_Start(&htim1, TIM_CHANNEL_2);
  HAL_TIM_PWM_Start(&htim1, TIM_CHANNEL_3);
  HAL_TIM_PWM_Start(&htim1, TIM_CHANNEL_4);

  HAL_TIM_Base_Start(&htim23);
  HAL_TIM_PWM_Start(&htim23, TIM_CHANNEL_1);
  HAL_TIM_PWM_Start(&htim23, TIM_CHANNEL_2);
  HAL_TIM_PWM_Start(&htim23, TIM_CHANNEL_3);
  HAL_TIM_PWM_Start(&htim23, TIM_CHANNEL_4);
  uint16_t constant = 1000;
  uint16_t count = 100;
  HAL_GPIO_WritePin(GPIOE, GPIO_PIN_2, 0);
  HAL_GPIO_WritePin(GPIOE, GPIO_PIN_3, 0);
  HAL_GPIO_WritePin(GPIOE, GPIO_PIN_4, 0);
  HAL_GPIO_WritePin(GPIOE, GPIO_PIN_5, 0);
  HAL_GPIO_WritePin(GPIOE, GPIO_PIN_6, 0);
  bsp_can_init();
  //usart_Init();
  uint8_t CAN_Data = 125;
  uint8_t CAN_State = -1;

  /* USER CODE END 2 */

  /* Create the thread(s) */
  /* definition and creation of defaultTask */
  osThreadDef(defaultTask, StartDefaultTask, osPriorityNormal, 0, 1024);
  defaultTaskHandle = osThreadCreate(osThread(defaultTask), NULL);

  /* Start scheduler */
  osKernelStart();

  /* We should never get here as control is now taken by the scheduler */

  /* Infinite loop */
  /* USER CODE BEGIN WHILE */
  while (1)
  {
	  __HAL_TIM_SetCompare(&htim1, TIM_CHANNEL_1, count);
	  __HAL_TIM_SetCompare(&htim1, TIM_CHANNEL_2, count);
	  __HAL_TIM_SetCompare(&htim1, TIM_CHANNEL_3, count);
	  __HAL_TIM_SetCompare(&htim1, TIM_CHANNEL_4, count);

	  __HAL_TIM_SetCompare(&htim23, TIM_CHANNEL_1, constant);
	  __HAL_TIM_SetCompare(&htim23, TIM_CHANNEL_2, constant);
	  __HAL_TIM_SetCompare(&htim23, TIM_CHANNEL_3, constant);
	  __HAL_TIM_SetCompare(&htim23, TIM_CHANNEL_4, constant);
	  //count++;
	  if(count > 100) {
		  count = 10;
	  }

	  //HAL_GPIO_WritePin(GPIOE, GPIO_PIN_2, 1);
	  //HAL_GPIO_WritePin(GPIOE, GPIO_PIN_3, 1);
	  //HAL_GPIO_WritePin(GPIOE, GPIO_PIN_4, 1);
	  //HAL_GPIO_WritePin(GPIOE, GPIO_PIN_5, 1);
	  //HAL_GPIO_WritePin(GPIOE, GPIO_PIN_6, 1);

	  //HAL_Delay(50);

	  HAL_GPIO_TogglePin(GPIOE, GPIO_PIN_2);
	  HAL_GPIO_TogglePin(GPIOE, GPIO_PIN_3);
	  HAL_GPIO_TogglePin(GPIOE, GPIO_PIN_4);
	  HAL_GPIO_TogglePin(GPIOE, GPIO_PIN_5);
	  //HAL_UART_Transmit(&huart1, "UART 1", 6, 100);
	  //HAL_UART_Transmit(&huart2, "UART 2", 6, 100);
	  //HAL_UART_Transmit(&huart3, "UART 3", 6, 100); //use this for debugging
	  //CAN_State = fdcanx_send_data(&hfdcan1, 0x01, &CAN_Data, 8);
	  //usart_printf("CAN_State=%d \r\n", CAN_State);

	  HAL_Delay(500);
	  //usart_printf("ABC\r\n",100);
    /* USER CODE END WHILE */

  }
}

void SystemClock_Config(void)
{
  RCC_OscInitTypeDef RCC_OscInitStruct = {0};
  RCC_ClkInitTypeDef RCC_ClkInitStruct = {0};

  /** Supply configuration update enable
  */
  HAL_PWREx_ConfigSupply(PWR_LDO_SUPPLY);

  /** Configure the main internal regulator output voltage
  */
  __HAL_PWR_VOLTAGESCALING_CONFIG(PWR_REGULATOR_VOLTAGE_SCALE0);

  while(!__HAL_PWR_GET_FLAG(PWR_FLAG_VOSRDY)) {}

  /** Initializes the RCC Oscillators according to the specified parameters
  * in the RCC_OscInitTypeDef structure.
  */
  RCC_OscInitStruct.OscillatorType = RCC_OSCILLATORTYPE_HSE;
  RCC_OscInitStruct.HSEState = RCC_HSE_ON;
  RCC_OscInitStruct.PLL.PLLState = RCC_PLL_ON;
  RCC_OscInitStruct.PLL.PLLSource = RCC_PLLSOURCE_HSE;
  RCC_OscInitStruct.PLL.PLLM = 1;
  RCC_OscInitStruct.PLL.PLLN = 64;
  RCC_OscInitStruct.PLL.PLLP = 3;
  RCC_OscInitStruct.PLL.PLLQ = 6;
  RCC_OscInitStruct.PLL.PLLR = 2;
  RCC_OscInitStruct.PLL.PLLRGE = RCC_PLL1VCIRANGE_3;
  RCC_OscInitStruct.PLL.PLLVCOSEL = RCC_PLL1VCOWIDE;
  RCC_OscInitStruct.PLL.PLLFRACN = 0;
  if (HAL_RCC_OscConfig(&RCC_OscInitStruct) != HAL_OK)
  {
    Error_Handler();
  }

  /** Initializes the CPU, AHB and APB buses clocks
  */
  RCC_ClkInitStruct.ClockType = RCC_CLOCKTYPE_HCLK|RCC_CLOCKTYPE_SYSCLK
                              |RCC_CLOCKTYPE_PCLK1|RCC_CLOCKTYPE_PCLK2
                              |RCC_CLOCKTYPE_D3PCLK1|RCC_CLOCKTYPE_D1PCLK1;
  RCC_ClkInitStruct.SYSCLKSource = RCC_SYSCLKSOURCE_PLLCLK;
  RCC_ClkInitStruct.SYSCLKDivider = RCC_SYSCLK_DIV1;
  RCC_ClkInitStruct.AHBCLKDivider = RCC_HCLK_DIV1;
  RCC_ClkInitStruct.APB3CLKDivider = RCC_APB3_DIV2;
  RCC_ClkInitStruct.APB1CLKDivider = RCC_APB1_DIV2;
  RCC_ClkInitStruct.APB2CLKDivider = RCC_APB2_DIV2;
  RCC_ClkInitStruct.APB4CLKDivider = RCC_APB4_DIV2;

  if (HAL_RCC_ClockConfig(&RCC_ClkInitStruct, FLASH_LATENCY_3) != HAL_OK)
  {
    Error_Handler();
  }
}

void PeriphCommonClock_Config(void)
{
  RCC_PeriphCLKInitTypeDef PeriphClkInitStruct = {0};

  /** Initializes the peripherals clock
  */
  PeriphClkInitStruct.PeriphClockSelection = RCC_PERIPHCLK_ADC|RCC_PERIPHCLK_FDCAN;
  PeriphClkInitStruct.PLL2.PLL2M = 1;
  PeriphClkInitStruct.PLL2.PLL2N = 21;
  PeriphClkInitStruct.PLL2.PLL2P = 2;
  PeriphClkInitStruct.PLL2.PLL2Q = 2;
  PeriphClkInitStruct.PLL2.PLL2R = 2;
  PeriphClkInitStruct.PLL2.PLL2RGE = RCC_PLL2VCIRANGE_3;
  PeriphClkInitStruct.PLL2.PLL2VCOSEL = RCC_PLL2VCOWIDE;
  PeriphClkInitStruct.PLL2.PLL2FRACN = 0;
  PeriphClkInitStruct.FdcanClockSelection = RCC_FDCANCLKSOURCE_PLL2;
  PeriphClkInitStruct.AdcClockSelection = RCC_ADCCLKSOURCE_PLL2;
  if (HAL_RCCEx_PeriphCLKConfig(&PeriphClkInitStruct) != HAL_OK)
  {
    Error_Handler();
  }
}

static void MX_ADC1_Init(void)
{

  ADC_MultiModeTypeDef multimode = {0};
  ADC_ChannelConfTypeDef sConfig = {0};

  /** Common config
  */
  hadc1.Instance = ADC1;
  hadc1.Init.ClockPrescaler = ADC_CLOCK_ASYNC_DIV128;
  hadc1.Init.Resolution = ADC_RESOLUTION_16B;
  hadc1.Init.ScanConvMode = ADC_SCAN_ENABLE;
  hadc1.Init.EOCSelection = ADC_EOC_SINGLE_CONV;
  hadc1.Init.LowPowerAutoWait = DISABLE;
  hadc1.Init.ContinuousConvMode = ENABLE;
  hadc1.Init.NbrOfConversion = 4;
  hadc1.Init.DiscontinuousConvMode = DISABLE;
  hadc1.Init.ExternalTrigConv = ADC_SOFTWARE_START;
  hadc1.Init.ExternalTrigConvEdge = ADC_EXTERNALTRIGCONVEDGE_NONE;
  hadc1.Init.ConversionDataManagement = ADC_CONVERSIONDATA_DMA_CIRCULAR;
  hadc1.Init.Overrun = ADC_OVR_DATA_PRESERVED;
  hadc1.Init.LeftBitShift = ADC_LEFTBITSHIFT_NONE;
  hadc1.Init.OversamplingMode = DISABLE;
  hadc1.Init.Oversampling.Ratio = 1;
  if (HAL_ADC_Init(&hadc1) != HAL_OK)
  {
    Error_Handler();
  }

  /** Configure the ADC multi-mode
  */
  multimode.Mode = ADC_MODE_INDEPENDENT;
  if (HAL_ADCEx_MultiModeConfigChannel(&hadc1, &multimode) != HAL_OK)
  {
    Error_Handler();
  }

  /** Configure Regular Channel
  */
  sConfig.Channel = ADC_CHANNEL_4;
  sConfig.Rank = ADC_REGULAR_RANK_1;
  sConfig.SamplingTime = ADC_SAMPLETIME_32CYCLES_5;
  sConfig.SingleDiff = ADC_SINGLE_ENDED;
  sConfig.OffsetNumber = ADC_OFFSET_NONE;
  sConfig.Offset = 0;
  sConfig.OffsetSignedSaturation = DISABLE;
  if (HAL_ADC_ConfigChannel(&hadc1, &sConfig) != HAL_OK)
  {
    Error_Handler();
  }

  /** Configure Regular Channel
  */
  sConfig.Channel = ADC_CHANNEL_2;
  sConfig.Rank = ADC_REGULAR_RANK_2;
  if (HAL_ADC_ConfigChannel(&hadc1, &sConfig) != HAL_OK)
  {
    Error_Handler();
  }

  /** Configure Regular Channel
  */
  sConfig.Channel = ADC_CHANNEL_3;
  sConfig.Rank = ADC_REGULAR_RANK_3;
  if (HAL_ADC_ConfigChannel(&hadc1, &sConfig) != HAL_OK)
  {
    Error_Handler();
  }

  /** Configure Regular Channel
  */
  sConfig.Channel = ADC_CHANNEL_5;
  sConfig.Rank = ADC_REGULAR_RANK_4;
  if (HAL_ADC_ConfigChannel(&hadc1, &sConfig) != HAL_OK)
  {
    Error_Handler();
  }

}

static void MX_ADC2_Init(void)
{

  ADC_ChannelConfTypeDef sConfig = {0};

  /** Common config
  */
  hadc2.Instance = ADC2;
  hadc2.Init.ClockPrescaler = ADC_CLOCK_ASYNC_DIV128;
  hadc2.Init.Resolution = ADC_RESOLUTION_16B;
  hadc2.Init.ScanConvMode = ADC_SCAN_ENABLE;
  hadc2.Init.EOCSelection = ADC_EOC_SINGLE_CONV;
  hadc2.Init.LowPowerAutoWait = DISABLE;
  hadc2.Init.ContinuousConvMode = ENABLE;
  hadc2.Init.NbrOfConversion = 2;
  hadc2.Init.DiscontinuousConvMode = DISABLE;
  hadc2.Init.ExternalTrigConv = ADC_SOFTWARE_START;
  hadc2.Init.ExternalTrigConvEdge = ADC_EXTERNALTRIGCONVEDGE_NONE;
  hadc2.Init.ConversionDataManagement = ADC_CONVERSIONDATA_DMA_CIRCULAR;
  hadc2.Init.Overrun = ADC_OVR_DATA_PRESERVED;
  hadc2.Init.LeftBitShift = ADC_LEFTBITSHIFT_NONE;
  hadc2.Init.OversamplingMode = DISABLE;
  hadc2.Init.Oversampling.Ratio = 1;
  if (HAL_ADC_Init(&hadc2) != HAL_OK)
  {
    Error_Handler();
  }

  /** Configure Regular Channel
  */
  sConfig.Channel = ADC_CHANNEL_2;
  sConfig.Rank = ADC_REGULAR_RANK_1;
  sConfig.SamplingTime = ADC_SAMPLETIME_16CYCLES_5;
  sConfig.SingleDiff = ADC_SINGLE_ENDED;
  sConfig.OffsetNumber = ADC_OFFSET_NONE;
  sConfig.Offset = 0;
  sConfig.OffsetSignedSaturation = DISABLE;
  if (HAL_ADC_ConfigChannel(&hadc2, &sConfig) != HAL_OK)
  {
    Error_Handler();
  }

  /** Configure Regular Channel
  */
  sConfig.Rank = ADC_REGULAR_RANK_2;
  if (HAL_ADC_ConfigChannel(&hadc2, &sConfig) != HAL_OK)
  {
    Error_Handler();
  }

}

static void MX_FDCAN1_Init(void)
{

  hfdcan1.Instance = FDCAN1;
  hfdcan1.Init.FrameFormat = FDCAN_FRAME_CLASSIC;
  hfdcan1.Init.Mode = FDCAN_MODE_NORMAL;
  hfdcan1.Init.AutoRetransmission = DISABLE;
  hfdcan1.Init.TransmitPause = DISABLE;
  hfdcan1.Init.ProtocolException = DISABLE;
  hfdcan1.Init.NominalPrescaler = 6;
  hfdcan1.Init.NominalSyncJumpWidth = 5;
  hfdcan1.Init.NominalTimeSeg1 = 15;
  hfdcan1.Init.NominalTimeSeg2 = 5;
  hfdcan1.Init.DataPrescaler = 6;
  hfdcan1.Init.DataSyncJumpWidth = 5;
  hfdcan1.Init.DataTimeSeg1 = 15;
  hfdcan1.Init.DataTimeSeg2 = 5;
  hfdcan1.Init.MessageRAMOffset = 0;
  hfdcan1.Init.StdFiltersNbr = 1;
  hfdcan1.Init.ExtFiltersNbr = 0;
  hfdcan1.Init.RxFifo0ElmtsNbr = 4;
  hfdcan1.Init.RxFifo0ElmtSize = FDCAN_DATA_BYTES_8;
  hfdcan1.Init.RxFifo1ElmtsNbr = 4;
  hfdcan1.Init.RxFifo1ElmtSize = FDCAN_DATA_BYTES_8;
  hfdcan1.Init.RxBuffersNbr = 4;
  hfdcan1.Init.RxBufferSize = FDCAN_DATA_BYTES_8;
  hfdcan1.Init.TxEventsNbr = 4;
  hfdcan1.Init.TxBuffersNbr = 8;
  hfdcan1.Init.TxFifoQueueElmtsNbr = 8;
  hfdcan1.Init.TxFifoQueueMode = FDCAN_TX_FIFO_OPERATION;
  hfdcan1.Init.TxElmtSize = FDCAN_DATA_BYTES_8;
  if (HAL_FDCAN_Init(&hfdcan1) != HAL_OK)
  {
    Error_Handler();
  }

}

static void MX_FDCAN2_Init(void)
{

  hfdcan2.Instance = FDCAN2;
  hfdcan2.Init.FrameFormat = FDCAN_FRAME_CLASSIC;
  hfdcan2.Init.Mode = FDCAN_MODE_NORMAL;
  hfdcan2.Init.AutoRetransmission = DISABLE;
  hfdcan2.Init.TransmitPause = DISABLE;
  hfdcan2.Init.ProtocolException = DISABLE;
  hfdcan2.Init.NominalPrescaler = 6;
  hfdcan2.Init.NominalSyncJumpWidth = 5;
  hfdcan2.Init.NominalTimeSeg1 = 15;
  hfdcan2.Init.NominalTimeSeg2 = 5;
  hfdcan2.Init.DataPrescaler = 6;
  hfdcan2.Init.DataSyncJumpWidth = 5;
  hfdcan2.Init.DataTimeSeg1 = 15;
  hfdcan2.Init.DataTimeSeg2 = 5;
  hfdcan2.Init.MessageRAMOffset = 0x406;
  hfdcan2.Init.StdFiltersNbr = 1;
  hfdcan2.Init.ExtFiltersNbr = 0;
  hfdcan2.Init.RxFifo0ElmtsNbr = 4;
  hfdcan2.Init.RxFifo0ElmtSize = FDCAN_DATA_BYTES_8;
  hfdcan2.Init.RxFifo1ElmtsNbr = 4;
  hfdcan2.Init.RxFifo1ElmtSize = FDCAN_DATA_BYTES_8;
  hfdcan2.Init.RxBuffersNbr = 4;
  hfdcan2.Init.RxBufferSize = FDCAN_DATA_BYTES_8;
  hfdcan2.Init.TxEventsNbr = 4;
  hfdcan2.Init.TxBuffersNbr = 8;
  hfdcan2.Init.TxFifoQueueElmtsNbr = 8;
  hfdcan2.Init.TxFifoQueueMode = FDCAN_TX_FIFO_OPERATION;
  hfdcan2.Init.TxElmtSize = FDCAN_DATA_BYTES_8;
  if (HAL_FDCAN_Init(&hfdcan2) != HAL_OK)
  {
    Error_Handler();
  }

}

static void MX_FDCAN3_Init(void)
{

  hfdcan3.Instance = FDCAN3;
  hfdcan3.Init.FrameFormat = FDCAN_FRAME_CLASSIC;
  hfdcan3.Init.Mode = FDCAN_MODE_NORMAL;
  hfdcan3.Init.AutoRetransmission = DISABLE;
  hfdcan3.Init.TransmitPause = DISABLE;
  hfdcan3.Init.ProtocolException = DISABLE;
  hfdcan3.Init.NominalPrescaler = 6;
  hfdcan3.Init.NominalSyncJumpWidth = 5;
  hfdcan3.Init.NominalTimeSeg1 = 15;
  hfdcan3.Init.NominalTimeSeg2 = 5;
  hfdcan3.Init.DataPrescaler = 6;
  hfdcan3.Init.DataSyncJumpWidth = 5;
  hfdcan3.Init.DataTimeSeg1 = 15;
  hfdcan3.Init.DataTimeSeg2 = 5;
  hfdcan3.Init.MessageRAMOffset = 0x812;
  hfdcan3.Init.StdFiltersNbr = 1;
  hfdcan3.Init.ExtFiltersNbr = 0;
  hfdcan3.Init.RxFifo0ElmtsNbr = 4;
  hfdcan3.Init.RxFifo0ElmtSize = FDCAN_DATA_BYTES_8;
  hfdcan3.Init.RxFifo1ElmtsNbr = 4;
  hfdcan3.Init.RxFifo1ElmtSize = FDCAN_DATA_BYTES_8;
  hfdcan3.Init.RxBuffersNbr = 4;
  hfdcan3.Init.RxBufferSize = FDCAN_DATA_BYTES_8;
  hfdcan3.Init.TxEventsNbr = 4;
  hfdcan3.Init.TxBuffersNbr = 8;
  hfdcan3.Init.TxFifoQueueElmtsNbr = 8;
  hfdcan3.Init.TxFifoQueueMode = FDCAN_TX_FIFO_OPERATION;
  hfdcan3.Init.TxElmtSize = FDCAN_DATA_BYTES_8;
  if (HAL_FDCAN_Init(&hfdcan3) != HAL_OK)
  {
    Error_Handler();
  }

}

static void MX_I2C2_Init(void)
{

  hi2c2.Instance = I2C2;
  hi2c2.Init.Timing = 0x20A0C4DF;
  hi2c2.Init.OwnAddress1 = 0;
  hi2c2.Init.AddressingMode = I2C_ADDRESSINGMODE_7BIT;
  hi2c2.Init.DualAddressMode = I2C_DUALADDRESS_DISABLE;
  hi2c2.Init.OwnAddress2 = 0;
  hi2c2.Init.OwnAddress2Masks = I2C_OA2_NOMASK;
  hi2c2.Init.GeneralCallMode = I2C_GENERALCALL_DISABLE;
  hi2c2.Init.NoStretchMode = I2C_NOSTRETCH_DISABLE;
  if (HAL_I2C_Init(&hi2c2) != HAL_OK)
  {
    Error_Handler();
  }

  /** Configure Analogue filter
  */
  if (HAL_I2CEx_ConfigAnalogFilter(&hi2c2, I2C_ANALOGFILTER_ENABLE) != HAL_OK)
  {
    Error_Handler();
  }

  /** Configure Digital filter
  */
  if (HAL_I2CEx_ConfigDigitalFilter(&hi2c2, 0) != HAL_OK)
  {
    Error_Handler();
  }

}

static void MX_I2C4_Init(void)
{

  hi2c4.Instance = I2C4;
  hi2c4.Init.Timing = 0x20A0C4DF;
  hi2c4.Init.OwnAddress1 = 0;
  hi2c4.Init.AddressingMode = I2C_ADDRESSINGMODE_7BIT;
  hi2c4.Init.DualAddressMode = I2C_DUALADDRESS_DISABLE;
  hi2c4.Init.OwnAddress2 = 0;
  hi2c4.Init.OwnAddress2Masks = I2C_OA2_NOMASK;
  hi2c4.Init.GeneralCallMode = I2C_GENERALCALL_DISABLE;
  hi2c4.Init.NoStretchMode = I2C_NOSTRETCH_DISABLE;
  if (HAL_I2C_Init(&hi2c4) != HAL_OK)
  {
    Error_Handler();
  }

  /** Configure Analogue filter
  */
  if (HAL_I2CEx_ConfigAnalogFilter(&hi2c4, I2C_ANALOGFILTER_ENABLE) != HAL_OK)
  {
    Error_Handler();
  }

  /** Configure Digital filter
  */
  if (HAL_I2CEx_ConfigDigitalFilter(&hi2c4, 0) != HAL_OK)
  {
    Error_Handler();
  }

}

static void MX_OPAMP1_Init(void)
{

  hopamp1.Instance = OPAMP1;
  hopamp1.Init.Mode = OPAMP_STANDALONE_MODE;
  hopamp1.Init.NonInvertingInput = OPAMP_NONINVERTINGINPUT_IO0;
  hopamp1.Init.InvertingInput = OPAMP_INVERTINGINPUT_IO0;
  hopamp1.Init.PowerMode = OPAMP_POWERMODE_NORMAL;
  hopamp1.Init.UserTrimming = OPAMP_TRIMMING_FACTORY;
  if (HAL_OPAMP_Init(&hopamp1) != HAL_OK)
  {
    Error_Handler();
  }

}

static void MX_OPAMP2_Init(void)
{

  hopamp2.Instance = OPAMP2;
  hopamp2.Init.Mode = OPAMP_STANDALONE_MODE;
  hopamp2.Init.NonInvertingInput = OPAMP_NONINVERTINGINPUT_IO0;
  hopamp2.Init.PowerMode = OPAMP_POWERMODE_NORMAL;
  hopamp2.Init.UserTrimming = OPAMP_TRIMMING_FACTORY;
  if (HAL_OPAMP_Init(&hopamp2) != HAL_OK)
  {
    Error_Handler();
  }

}

static void MX_TIM1_Init(void)
{

  TIM_ClockConfigTypeDef sClockSourceConfig = {0};
  TIM_MasterConfigTypeDef sMasterConfig = {0};
  TIM_OC_InitTypeDef sConfigOC = {0};
  TIM_BreakDeadTimeConfigTypeDef sBreakDeadTimeConfig = {0};

  htim1.Instance = TIM1;
  htim1.Init.Prescaler = 256-1;
  htim1.Init.CounterMode = TIM_COUNTERMODE_UP;
  htim1.Init.Period = 200-1;
  htim1.Init.ClockDivision = TIM_CLOCKDIVISION_DIV1;
  htim1.Init.RepetitionCounter = 0;
  htim1.Init.AutoReloadPreload = TIM_AUTORELOAD_PRELOAD_ENABLE;
  if (HAL_TIM_Base_Init(&htim1) != HAL_OK)
  {
    Error_Handler();
  }
  sClockSourceConfig.ClockSource = TIM_CLOCKSOURCE_INTERNAL;
  if (HAL_TIM_ConfigClockSource(&htim1, &sClockSourceConfig) != HAL_OK)
  {
    Error_Handler();
  }
  if (HAL_TIM_PWM_Init(&htim1) != HAL_OK)
  {
    Error_Handler();
  }
  sMasterConfig.MasterOutputTrigger = TIM_TRGO_RESET;
  sMasterConfig.MasterOutputTrigger2 = TIM_TRGO2_RESET;
  sMasterConfig.MasterSlaveMode = TIM_MASTERSLAVEMODE_DISABLE;
  if (HAL_TIMEx_MasterConfigSynchronization(&htim1, &sMasterConfig) != HAL_OK)
  {
    Error_Handler();
  }
  sConfigOC.OCMode = TIM_OCMODE_PWM1;
  sConfigOC.Pulse = 100-1;
  sConfigOC.OCPolarity = TIM_OCPOLARITY_HIGH;
  sConfigOC.OCNPolarity = TIM_OCNPOLARITY_HIGH;
  sConfigOC.OCFastMode = TIM_OCFAST_DISABLE;
  sConfigOC.OCIdleState = TIM_OCIDLESTATE_RESET;
  sConfigOC.OCNIdleState = TIM_OCNIDLESTATE_RESET;
  if (HAL_TIM_PWM_ConfigChannel(&htim1, &sConfigOC, TIM_CHANNEL_1) != HAL_OK)
  {
    Error_Handler();
  }
  if (HAL_TIM_PWM_ConfigChannel(&htim1, &sConfigOC, TIM_CHANNEL_2) != HAL_OK)
  {
    Error_Handler();
  }
  if (HAL_TIM_PWM_ConfigChannel(&htim1, &sConfigOC, TIM_CHANNEL_3) != HAL_OK)
  {
    Error_Handler();
  }
  if (HAL_TIM_PWM_ConfigChannel(&htim1, &sConfigOC, TIM_CHANNEL_4) != HAL_OK)
  {
    Error_Handler();
  }
  sBreakDeadTimeConfig.OffStateRunMode = TIM_OSSR_DISABLE;
  sBreakDeadTimeConfig.OffStateIDLEMode = TIM_OSSI_DISABLE;
  sBreakDeadTimeConfig.LockLevel = TIM_LOCKLEVEL_OFF;
  sBreakDeadTimeConfig.DeadTime = 0;
  sBreakDeadTimeConfig.BreakState = TIM_BREAK_DISABLE;
  sBreakDeadTimeConfig.BreakPolarity = TIM_BREAKPOLARITY_HIGH;
  sBreakDeadTimeConfig.BreakFilter = 0;
  sBreakDeadTimeConfig.Break2State = TIM_BREAK2_DISABLE;
  sBreakDeadTimeConfig.Break2Polarity = TIM_BREAK2POLARITY_HIGH;
  sBreakDeadTimeConfig.Break2Filter = 0;
  sBreakDeadTimeConfig.AutomaticOutput = TIM_AUTOMATICOUTPUT_DISABLE;
  if (HAL_TIMEx_ConfigBreakDeadTime(&htim1, &sBreakDeadTimeConfig) != HAL_OK)
  {
    Error_Handler();
  }
  HAL_TIM_MspPostInit(&htim1);

}

static void MX_TIM2_Init(void)
{

  TIM_MasterConfigTypeDef sMasterConfig = {0};
  TIM_OC_InitTypeDef sConfigOC = {0};

  htim2.Instance = TIM2;
  htim2.Init.Prescaler = 0;
  htim2.Init.CounterMode = TIM_COUNTERMODE_UP;
  htim2.Init.Period = 4294967295;
  htim2.Init.ClockDivision = TIM_CLOCKDIVISION_DIV1;
  htim2.Init.AutoReloadPreload = TIM_AUTORELOAD_PRELOAD_DISABLE;
  if (HAL_TIM_PWM_Init(&htim2) != HAL_OK)
  {
    Error_Handler();
  }
  sMasterConfig.MasterOutputTrigger = TIM_TRGO_RESET;
  sMasterConfig.MasterSlaveMode = TIM_MASTERSLAVEMODE_DISABLE;
  if (HAL_TIMEx_MasterConfigSynchronization(&htim2, &sMasterConfig) != HAL_OK)
  {
    Error_Handler();
  }
  sConfigOC.OCMode = TIM_OCMODE_PWM1;
  sConfigOC.Pulse = 0;
  sConfigOC.OCPolarity = TIM_OCPOLARITY_HIGH;
  sConfigOC.OCFastMode = TIM_OCFAST_DISABLE;
  if (HAL_TIM_PWM_ConfigChannel(&htim2, &sConfigOC, TIM_CHANNEL_1) != HAL_OK)
  {
    Error_Handler();
  }
  if (HAL_TIM_PWM_ConfigChannel(&htim2, &sConfigOC, TIM_CHANNEL_2) != HAL_OK)
  {
    Error_Handler();
  }
  if (HAL_TIM_PWM_ConfigChannel(&htim2, &sConfigOC, TIM_CHANNEL_3) != HAL_OK)
  {
    Error_Handler();
  }
  HAL_TIM_MspPostInit(&htim2);

}

static void MX_TIM3_Init(void)
{

  TIM_MasterConfigTypeDef sMasterConfig = {0};
  TIM_OC_InitTypeDef sConfigOC = {0};

  htim3.Instance = TIM3;
  htim3.Init.Prescaler = 0;
  htim3.Init.CounterMode = TIM_COUNTERMODE_UP;
  htim3.Init.Period = 65535;
  htim3.Init.ClockDivision = TIM_CLOCKDIVISION_DIV1;
  htim3.Init.AutoReloadPreload = TIM_AUTORELOAD_PRELOAD_DISABLE;
  if (HAL_TIM_PWM_Init(&htim3) != HAL_OK)
  {
    Error_Handler();
  }
  sMasterConfig.MasterOutputTrigger = TIM_TRGO_RESET;
  sMasterConfig.MasterSlaveMode = TIM_MASTERSLAVEMODE_DISABLE;
  if (HAL_TIMEx_MasterConfigSynchronization(&htim3, &sMasterConfig) != HAL_OK)
  {
    Error_Handler();
  }
  sConfigOC.OCMode = TIM_OCMODE_PWM1;
  sConfigOC.Pulse = 0;
  sConfigOC.OCPolarity = TIM_OCPOLARITY_HIGH;
  sConfigOC.OCFastMode = TIM_OCFAST_DISABLE;
  if (HAL_TIM_PWM_ConfigChannel(&htim3, &sConfigOC, TIM_CHANNEL_1) != HAL_OK)
  {
    Error_Handler();
  }
  if (HAL_TIM_PWM_ConfigChannel(&htim3, &sConfigOC, TIM_CHANNEL_2) != HAL_OK)
  {
    Error_Handler();
  }
  if (HAL_TIM_PWM_ConfigChannel(&htim3, &sConfigOC, TIM_CHANNEL_3) != HAL_OK)
  {
    Error_Handler();
  }
  if (HAL_TIM_PWM_ConfigChannel(&htim3, &sConfigOC, TIM_CHANNEL_4) != HAL_OK)
  {
    Error_Handler();
  }
  HAL_TIM_MspPostInit(&htim3);

}

static void MX_TIM23_Init(void)
{

  TIM_ClockConfigTypeDef sClockSourceConfig = {0};
  TIM_MasterConfigTypeDef sMasterConfig = {0};
  TIM_OC_InitTypeDef sConfigOC = {0};

  htim23.Instance = TIM23;
  htim23.Init.Prescaler = 256-1;
  htim23.Init.CounterMode = TIM_COUNTERMODE_UP;
  htim23.Init.Period = 20000-1;
  htim23.Init.ClockDivision = TIM_CLOCKDIVISION_DIV1;
  htim23.Init.AutoReloadPreload = TIM_AUTORELOAD_PRELOAD_ENABLE;
  if (HAL_TIM_Base_Init(&htim23) != HAL_OK)
  {
    Error_Handler();
  }
  sClockSourceConfig.ClockSource = TIM_CLOCKSOURCE_INTERNAL;
  if (HAL_TIM_ConfigClockSource(&htim23, &sClockSourceConfig) != HAL_OK)
  {
    Error_Handler();
  }
  if (HAL_TIM_PWM_Init(&htim23) != HAL_OK)
  {
    Error_Handler();
  }
  sMasterConfig.MasterOutputTrigger = TIM_TRGO_RESET;
  sMasterConfig.MasterSlaveMode = TIM_MASTERSLAVEMODE_DISABLE;
  if (HAL_TIMEx_MasterConfigSynchronization(&htim23, &sMasterConfig) != HAL_OK)
  {
    Error_Handler();
  }
  sConfigOC.OCMode = TIM_OCMODE_PWM1;
  sConfigOC.Pulse = 1000-1;
  sConfigOC.OCPolarity = TIM_OCPOLARITY_HIGH;
  sConfigOC.OCFastMode = TIM_OCFAST_DISABLE;
  if (HAL_TIM_PWM_ConfigChannel(&htim23, &sConfigOC, TIM_CHANNEL_1) != HAL_OK)
  {
    Error_Handler();
  }
  if (HAL_TIM_PWM_ConfigChannel(&htim23, &sConfigOC, TIM_CHANNEL_2) != HAL_OK)
  {
    Error_Handler();
  }
  if (HAL_TIM_PWM_ConfigChannel(&htim23, &sConfigOC, TIM_CHANNEL_3) != HAL_OK)
  {
    Error_Handler();
  }
  if (HAL_TIM_PWM_ConfigChannel(&htim23, &sConfigOC, TIM_CHANNEL_4) != HAL_OK)
  {
    Error_Handler();
  }
  HAL_TIM_MspPostInit(&htim23);

}

static void MX_UART7_Init(void)
{

  huart7.Instance = UART7;
  huart7.Init.BaudRate = 115200;
  huart7.Init.WordLength = UART_WORDLENGTH_8B;
  huart7.Init.StopBits = UART_STOPBITS_1;
  huart7.Init.Parity = UART_PARITY_NONE;
  huart7.Init.Mode = UART_MODE_TX_RX;
  huart7.Init.HwFlowCtl = UART_HWCONTROL_NONE;
  huart7.Init.OverSampling = UART_OVERSAMPLING_16;
  huart7.Init.OneBitSampling = UART_ONE_BIT_SAMPLE_DISABLE;
  huart7.Init.ClockPrescaler = UART_PRESCALER_DIV1;
  huart7.AdvancedInit.AdvFeatureInit = UART_ADVFEATURE_NO_INIT;
  if (HAL_RS485Ex_Init(&huart7, UART_DE_POLARITY_HIGH, 0, 0) != HAL_OK)
  {
    Error_Handler();
  }
  if (HAL_UARTEx_SetTxFifoThreshold(&huart7, UART_TXFIFO_THRESHOLD_1_8) != HAL_OK)
  {
    Error_Handler();
  }
  if (HAL_UARTEx_SetRxFifoThreshold(&huart7, UART_RXFIFO_THRESHOLD_1_8) != HAL_OK)
  {
    Error_Handler();
  }
  if (HAL_UARTEx_DisableFifoMode(&huart7) != HAL_OK)
  {
    Error_Handler();
  }

}

static void MX_UART8_Init(void)
{

  huart8.Instance = UART8;
  huart8.Init.BaudRate = 100000;
  huart8.Init.WordLength = UART_WORDLENGTH_8B;
  huart8.Init.StopBits = UART_STOPBITS_1;
  huart8.Init.Parity = UART_PARITY_EVEN;
  huart8.Init.Mode = UART_MODE_TX_RX;
  huart8.Init.HwFlowCtl = UART_HWCONTROL_NONE;
  huart8.Init.OverSampling = UART_OVERSAMPLING_16;
  huart8.Init.OneBitSampling = UART_ONE_BIT_SAMPLE_DISABLE;
  huart8.Init.ClockPrescaler = UART_PRESCALER_DIV1;
  huart8.AdvancedInit.AdvFeatureInit = UART_ADVFEATURE_NO_INIT;
  if (HAL_UART_Init(&huart8) != HAL_OK)
  {
    Error_Handler();
  }
  if (HAL_UARTEx_SetTxFifoThreshold(&huart8, UART_TXFIFO_THRESHOLD_1_8) != HAL_OK)
  {
    Error_Handler();
  }
  if (HAL_UARTEx_SetRxFifoThreshold(&huart8, UART_RXFIFO_THRESHOLD_1_8) != HAL_OK)
  {
    Error_Handler();
  }
  if (HAL_UARTEx_DisableFifoMode(&huart8) != HAL_OK)
  {
    Error_Handler();
  }

}

static void MX_USART1_UART_Init(void)
{

  huart1.Instance = USART1;
  huart1.Init.BaudRate = 115200;
  huart1.Init.WordLength = UART_WORDLENGTH_8B;
  huart1.Init.StopBits = UART_STOPBITS_1;
  huart1.Init.Parity = UART_PARITY_NONE;
  huart1.Init.Mode = UART_MODE_TX_RX;
  huart1.Init.HwFlowCtl = UART_HWCONTROL_NONE;
  huart1.Init.OverSampling = UART_OVERSAMPLING_16;
  huart1.Init.OneBitSampling = UART_ONE_BIT_SAMPLE_DISABLE;
  huart1.Init.ClockPrescaler = UART_PRESCALER_DIV1;
  huart1.AdvancedInit.AdvFeatureInit = UART_ADVFEATURE_NO_INIT;
  if (HAL_UART_Init(&huart1) != HAL_OK)
  {
    Error_Handler();
  }
  if (HAL_UARTEx_SetTxFifoThreshold(&huart1, UART_TXFIFO_THRESHOLD_1_8) != HAL_OK)
  {
    Error_Handler();
  }
  if (HAL_UARTEx_SetRxFifoThreshold(&huart1, UART_RXFIFO_THRESHOLD_1_8) != HAL_OK)
  {
    Error_Handler();
  }
  if (HAL_UARTEx_DisableFifoMode(&huart1) != HAL_OK)
  {
    Error_Handler();
  }

}

static void MX_USART2_UART_Init(void)
{

  huart2.Instance = USART2;
  huart2.Init.BaudRate = 115200;
  huart2.Init.WordLength = UART_WORDLENGTH_8B;
  huart2.Init.StopBits = UART_STOPBITS_1;
  huart2.Init.Parity = UART_PARITY_NONE;
  huart2.Init.Mode = UART_MODE_TX_RX;
  huart2.Init.HwFlowCtl = UART_HWCONTROL_NONE;
  huart2.Init.OverSampling = UART_OVERSAMPLING_16;
  huart2.Init.OneBitSampling = UART_ONE_BIT_SAMPLE_DISABLE;
  huart2.Init.ClockPrescaler = UART_PRESCALER_DIV1;
  huart2.AdvancedInit.AdvFeatureInit = UART_ADVFEATURE_NO_INIT;
  if (HAL_UART_Init(&huart2) != HAL_OK)
  {
    Error_Handler();
  }
  if (HAL_UARTEx_SetTxFifoThreshold(&huart2, UART_TXFIFO_THRESHOLD_1_8) != HAL_OK)
  {
    Error_Handler();
  }
  if (HAL_UARTEx_SetRxFifoThreshold(&huart2, UART_RXFIFO_THRESHOLD_1_8) != HAL_OK)
  {
    Error_Handler();
  }
  if (HAL_UARTEx_DisableFifoMode(&huart2) != HAL_OK)
  {
    Error_Handler();
  }

}

static void MX_USART3_UART_Init(void)
{

  huart3.Instance = USART3;
  huart3.Init.BaudRate = 115200;
  huart3.Init.WordLength = UART_WORDLENGTH_8B;
  huart3.Init.StopBits = UART_STOPBITS_1;
  huart3.Init.Parity = UART_PARITY_NONE;
  huart3.Init.Mode = UART_MODE_TX_RX;
  huart3.Init.HwFlowCtl = UART_HWCONTROL_NONE;
  huart3.Init.OverSampling = UART_OVERSAMPLING_16;
  huart3.Init.OneBitSampling = UART_ONE_BIT_SAMPLE_DISABLE;
  huart3.Init.ClockPrescaler = UART_PRESCALER_DIV1;
  huart3.AdvancedInit.AdvFeatureInit = UART_ADVFEATURE_NO_INIT;
  if (HAL_UART_Init(&huart3) != HAL_OK)
  {
    Error_Handler();
  }
  if (HAL_UARTEx_SetTxFifoThreshold(&huart3, UART_TXFIFO_THRESHOLD_1_8) != HAL_OK)
  {
    Error_Handler();
  }
  if (HAL_UARTEx_SetRxFifoThreshold(&huart3, UART_RXFIFO_THRESHOLD_1_8) != HAL_OK)
  {
    Error_Handler();
  }
  if (HAL_UARTEx_DisableFifoMode(&huart3) != HAL_OK)
  {
    Error_Handler();
  }

}

static void MX_USART10_UART_Init(void)
{

  huart10.Instance = USART10;
  huart10.Init.BaudRate = 115200;
  huart10.Init.WordLength = UART_WORDLENGTH_8B;
  huart10.Init.StopBits = UART_STOPBITS_1;
  huart10.Init.Parity = UART_PARITY_NONE;
  huart10.Init.Mode = UART_MODE_TX_RX;
  huart10.Init.HwFlowCtl = UART_HWCONTROL_NONE;
  huart10.Init.OverSampling = UART_OVERSAMPLING_16;
  huart10.Init.OneBitSampling = UART_ONE_BIT_SAMPLE_DISABLE;
  huart10.Init.ClockPrescaler = UART_PRESCALER_DIV1;
  huart10.AdvancedInit.AdvFeatureInit = UART_ADVFEATURE_NO_INIT;
  if (HAL_RS485Ex_Init(&huart10, UART_DE_POLARITY_HIGH, 0, 0) != HAL_OK)
  {
    Error_Handler();
  }
  if (HAL_UARTEx_SetTxFifoThreshold(&huart10, UART_TXFIFO_THRESHOLD_1_8) != HAL_OK)
  {
    Error_Handler();
  }
  if (HAL_UARTEx_SetRxFifoThreshold(&huart10, UART_RXFIFO_THRESHOLD_1_8) != HAL_OK)
  {
    Error_Handler();
  }
  if (HAL_UARTEx_DisableFifoMode(&huart10) != HAL_OK)
  {
    Error_Handler();
  }

}

static void MX_DMA_Init(void)
{

  /* DMA controller clock enable */
  __HAL_RCC_DMA1_CLK_ENABLE();
  __HAL_RCC_DMA2_CLK_ENABLE();

  /* DMA interrupt init */
  /* DMA1_Stream0_IRQn interrupt configuration */
  HAL_NVIC_SetPriority(DMA1_Stream0_IRQn, 5, 0);
  HAL_NVIC_EnableIRQ(DMA1_Stream0_IRQn);
  /* DMA1_Stream1_IRQn interrupt configuration */
  HAL_NVIC_SetPriority(DMA1_Stream1_IRQn, 5, 0);
  HAL_NVIC_EnableIRQ(DMA1_Stream1_IRQn);
  /* DMA1_Stream2_IRQn interrupt configuration */
  HAL_NVIC_SetPriority(DMA1_Stream2_IRQn, 5, 0);
  HAL_NVIC_EnableIRQ(DMA1_Stream2_IRQn);
  /* DMA1_Stream3_IRQn interrupt configuration */
  HAL_NVIC_SetPriority(DMA1_Stream3_IRQn, 5, 0);
  HAL_NVIC_EnableIRQ(DMA1_Stream3_IRQn);
  /* DMA1_Stream4_IRQn interrupt configuration */
  HAL_NVIC_SetPriority(DMA1_Stream4_IRQn, 5, 0);
  HAL_NVIC_EnableIRQ(DMA1_Stream4_IRQn);
  /* DMA1_Stream5_IRQn interrupt configuration */
  HAL_NVIC_SetPriority(DMA1_Stream5_IRQn, 5, 0);
  HAL_NVIC_EnableIRQ(DMA1_Stream5_IRQn);
  /* DMA1_Stream6_IRQn interrupt configuration */
  HAL_NVIC_SetPriority(DMA1_Stream6_IRQn, 5, 0);
  HAL_NVIC_EnableIRQ(DMA1_Stream6_IRQn);
  /* DMA1_Stream7_IRQn interrupt configuration */
  HAL_NVIC_SetPriority(DMA1_Stream7_IRQn, 5, 0);
  HAL_NVIC_EnableIRQ(DMA1_Stream7_IRQn);
  /* DMA2_Stream0_IRQn interrupt configuration */
  HAL_NVIC_SetPriority(DMA2_Stream0_IRQn, 5, 0);
  HAL_NVIC_EnableIRQ(DMA2_Stream0_IRQn);

}

static void MX_GPIO_Init(void)
{
  GPIO_InitTypeDef GPIO_InitStruct = {0};

  /* GPIO Ports Clock Enable */
  __HAL_RCC_GPIOE_CLK_ENABLE();
  __HAL_RCC_GPIOF_CLK_ENABLE();
  __HAL_RCC_GPIOH_CLK_ENABLE();
  __HAL_RCC_GPIOA_CLK_ENABLE();
  __HAL_RCC_GPIOC_CLK_ENABLE();
  __HAL_RCC_GPIOB_CLK_ENABLE();
  __HAL_RCC_GPIOG_CLK_ENABLE();
  __HAL_RCC_GPIOD_CLK_ENABLE();

  /*Configure GPIO pin Output Level */
  HAL_GPIO_WritePin(GPIOE, GPIO_PIN_2|GPIO_PIN_3|GPIO_PIN_4|GPIO_PIN_5
                          |GPIO_PIN_6, GPIO_PIN_RESET);

  /*Configure GPIO pins : PE2 PE3 PE4 PE5
                           PE6 */
  GPIO_InitStruct.Pin = GPIO_PIN_2|GPIO_PIN_3|GPIO_PIN_4|GPIO_PIN_5
                          |GPIO_PIN_6;
  GPIO_InitStruct.Mode = GPIO_MODE_OUTPUT_PP;
  GPIO_InitStruct.Pull = GPIO_NOPULL;
  GPIO_InitStruct.Speed = GPIO_SPEED_FREQ_MEDIUM;
  HAL_GPIO_Init(GPIOE, &GPIO_InitStruct);

  /*Configure GPIO pins : PA3 PA4 PA5 */
  GPIO_InitStruct.Pin = GPIO_PIN_3|GPIO_PIN_4|GPIO_PIN_5;
  GPIO_InitStruct.Mode = GPIO_MODE_INPUT;
  GPIO_InitStruct.Pull = GPIO_NOPULL;
  HAL_GPIO_Init(GPIOA, &GPIO_InitStruct);

}

/* USER CODE BEGIN 4 */

float determiningTrigAngle (int16_t motorAngle[5]) {
	if (motorAngle[0] < 0 && motorAngle[1] < 0) {
		return (-M_PI + atanf(((float)motorAngle[0])/((float)motorAngle[1])));
	} else if (motorAngle[0] >= 0 && motorAngle[1] < 0) {
		return (M_PI + atanf(((float)motorAngle[0])/((float)motorAngle[1])));
	} else if (motorAngle[0] == 0 && motorAngle[1] == 0) {
		return 0;
	} else {
		return atanf(((float)motorAngle[0])/((float)motorAngle[1]));
	}
}

int16_t wheelRotation (int16_t currentRotation, int16_t destinationRotation) {
	int8_t newTargetRotationCounter = 0;
	int16_t ACD = abs(destinationRotation - currentRotation);
	int16_t ALD = abs((destinationRotation - 8191) - currentRotation);
	int16_t AUD = abs((destinationRotation + 8191) - currentRotation);
	if (ACD < ALD && ACD < AUD) { // Normal Delta is best case
		newTargetRotationCounter = 0;
	} else if (ALD < ACD && ALD < AUD) { // Lower Delta (Flip) is best case
		newTargetRotationCounter = -1;
	} else { // Upper Delta is best case here
		newTargetRotationCounter = 1;
	}
    return ((destinationRotation + (8191*newTargetRotationCounter)) - currentRotation);
}

float swerveScaler (int16_t motorInfo[4][5]) {
	int16_t largestVal = 0;
	for (int8_t i = 0; i < 4; i++) {
		if (motorInfo[i][2] > largestVal) {
			largestVal = motorInfo[i][2];
		}
	}

	// usart_printf("Hello %d there!\r\n", 5);
	if (largestVal <= maxValAllowed) {
		return 1;
	} else {
		return ((float)(maxValAllowed)/(float)(largestVal));
	}
}

int16_t PD (MotorType_ID motorType, int16_t *previousDelta, int16_t currentDelta, float kP, float kD) {

	return applyCtrlLimit(motorType, (currentDelta*kP + (*previousDelta - currentDelta)*kD));
}

void fondlerAutoReverse (int8_t allVars[5], int8_t RCSwitch, int8_t M2006IDX, int8_t reverseRotation, PID_preset_t indexerPreset) {
	int16_t flywheelSpeed = getMotorRPM(Bus1, M3508, 1);
    if ((/*(pc_control.left_button_down == 1) && */(flywheelSpeed > 7000) && (allVars[4] == 0)) || (RCSwitch == 1)) {
    	// setMotorRPM(Bus2, M2006, 6, (100), indexerPreset);
    	allVars[0] = 1;

		if (allVars[3] > 0 && allVars[2] == 0) {
			setMotorRPM(Bus1, M2006, M2006IDX, reverseRotation*15000, indexerPreset);
			allVars[3]--;
		} else {
			allVars[2] = 0;
			usart_printf("BeansOutput1\r\n");
			setMotorRPM(Bus1, M2006, M2006IDX, -270*16*reverseRotation, indexerPreset);
			if (reverseRotation == 1) {
				if (allVars[1] == 0 && getMotorRPM(Bus1, M2006, M2006IDX) <= -10) {
					allVars[1] = 1;
				} else if (getMotorRPM(Bus1, M2006, M2006IDX) > -1 && allVars[1] == 1) {         // jammed
					allVars[3] = 12;
					allVars[1] = 0;
				}
			} else {
				if (allVars[1] == 0 && getMotorRPM(Bus1, M2006, M2006IDX) >= 10) {
					allVars[1] = 1;
				} else if (getMotorRPM(Bus1, M2006, M2006IDX) < 1 && allVars[1] == 1) {         // jammed
					allVars[3] = 12;
					allVars[1] = 0;
				}
			}
		}
    } else {
    	allVars[0] = 0;
    	allVars[2] = 1;
    	allVars[1] = 0;
    	setMotorRPM(Bus1, M2006, M2006IDX, 0, indexerPreset);
    }
}

/* USER CODE END 4 */

void StartDefaultTask(void const * argument)
{
  /* USER CODE BEGIN 5 */
	uint8_t CAN_Data[] = {0x00, 0x01, 0x02, 0x03, 0x04, 0x05, 0x06, 0x07};
	uint32_t CAN_Extended_Header = 0xFFF0000;
	uint8_t CAN_Extended_Data = 0x00;
	uint8_t CAN_State = 0;
	uint16_t value_adc[] = {0, 0, 0, 0};
	uint16_t value_adc2[] = {0, 0};
	uint32_t voltage = 0;
	HAL_ADCEx_Calibration_Start(&hadc1, ADC_CALIB_OFFSET, ADC_SINGLE_ENDED);
	HAL_ADCEx_Calibration_Start(&hadc2, ADC_CALIB_OFFSET, ADC_SINGLE_ENDED);
	HAL_ADC_Start_DMA(&hadc1, (uint32_t *)value_adc, 4);
	HAL_ADC_Start_DMA(&hadc2, (uint32_t *)value_adc2, 2);
	HAL_OPAMP_Start(&hopamp1);
	HAL_OPAMP_Start(&hopamp2);
	//remote_control_init();
	/*
	osDelay(25000);
	//set_CANID_cybergear(&mi_motor[0], 0x34);          //DO NOT ENABLE - needs target motor CANID to be changed in cybergear.c to function

	init_cybergear(&mi_motor[0], 0x31, Speed_mode);
	osDelay(50);
	init_cybergear(&mi_motor[1], 0x32, Speed_mode);
	osDelay(50);
	init_cybergear(&mi_motor[2], 0x33, Speed_mode);
	osDelay(50);
	init_cybergear(&mi_motor[3], 0x34, Speed_mode);
	// set_maxCurrent_cybergear(&mi_motor[0], 1);
	//set_refSpd_cybergear(&mi_motor[0], 1);
	osDelay(500);
	*/

	PID_preset_t test = {8.0, 0.0, 0.0};
	PID_preset_t test2 = {50.0, 0.0, 0.0};

	//
	int16_t wheelPrev[8] = {0, 0, 0, 0, 0, 0, 0, 0};

	/*  Fronts
		3   0

		2   1
	*/

	int8_t rotationVectors[4][2] =  {{1,  1},
							 		 {-1,  1},
									 {-1,  -1},
									 {1, -1}};

	int16_t forwardsID[4] = {637, 7135, 6562, 2532};

	// [MotorID][0 = MotorXVal, 1 = MotorYVal, 2 = MotorABSVal, 3 = MotorConvertedAngle], 4 = Reversal Of Motor
	int16_t motorInfo[4][5];
	int16_t DP[3] = {0, 0, 0};
	int8_t noVelocity = 0;
	int8_t fondlerVars[5] = {0, 0, 0, 0, 0};

	//start_cybergear(&mi_motor[0]);
	//HAL_ADC_Stop(&hadc1);
	//value = map(ADC_VAL, 0, 65535, 0, 100);
  /* Infinite loop */
  for(;;)
  {
	  // fdcanx_send_data(&hfdcan1, CAN_b2b_A_RC_Val_ID, CAN_Data, 8);
	  // setMotorRPM(Bus1, GM6020, 1, 20, test2);
	  // usart_printf("%d\r\n", getMotorRPM(Bus1, GM6020, 1));
	  usart_printf("%d %d %d %d %d %d %d\r\n", getRCfakechannel(0), getRCfakechannel(1), getRCfakechannel(2), getRCfakechannel(3), getRCfakechannel(4), getRCfakechannel(5), getRCfakechannel(6));
	  // usart_printf("Beans Output?");
	  // usart_printf("%d\r\n", getRCfakechannel(4));
		//fdcanx_send_data(&hfdcan1, 0x01, &CAN_Data, 8);
		//CAN_State = fdcanx_send_extended(&hfdcan2, CAN_Extended_Header, &CAN_Extended_Data, 8);
	  	//set_refSpd_cybergear(&mi_motor[0], 10);
	  //setMotorRPM(Bus1, M3508, 1, 2000, indexerPreset);

	  int16_t FB = 1*getRCfakechannel(0);
	  int16_t LR = -1*getRCfakechannel(1);
	  int16_t Rotate = -1*getRCfakechannel(3);

	  // int8_t altDrivingMode = getRCswitch(0);

	  if (FB == 0 && LR == 0 && Rotate == 0) {
		  FB = DP[0];
	  	  LR = DP[1];
	  	  Rotate = DP[2];
	  	  noVelocity = 1;
	  } else {
		  noVelocity = 0;
	  }
	  DP[0] = FB;
	  DP[1] = LR;
	  DP[2] = Rotate;
// usart_printf("%d\r\n", altDrivingMode);
	  for (int8_t i = 0; i < 4; i++ ) {
		  motorInfo[i][0] = LR + (Rotate * rotationVectors[i][0]);
		  motorInfo[i][1] = FB + (Rotate * rotationVectors[i][1]);
		  if (noVelocity == 0) {
			  motorInfo[i][2] = (int16_t)(sqrtf((float)((motorInfo[i][0]*motorInfo[i][0])+(motorInfo[i][1]*motorInfo[i][1]))));
		  } else {
			  motorInfo[i][2] = 0;
		  }
	  }

	  float SScalerVal = swerveScaler(motorInfo);

	  // Swerve Motor
	  for (int8_t j = 0; j < 4; j++) {
		  // Scales Motor Speed Output
		  // 800*11.25 = 9000
		  motorInfo[j][2] = (float)motorInfo[j][2] * SScalerVal * 11.25;

		  int16_t trigAng = (int16_t)(4095.5f*(determiningTrigAngle(motorInfo[j])/M_PI));

		  int16_t tempAngle = trigAng+forwardsID[j];
		  if (tempAngle > 8191) {
			  tempAngle = tempAngle-8191;
		  } else if (tempAngle < 0) {
			  tempAngle = tempAngle+8191;
		  }
		  motorInfo[j][3] = tempAngle;
	  }

	  // Drive Motor

	  for (int8_t k = 0; k < 4; k++) {
		  // CAN_setMotorCtrlVal(Bus1, GM6020, k+1, PD(GM6020, &wheelPrev[k], wheelRotation (getRotorPosition(Bus1, GM6020, k+1), motorInfo[k][3]), 40, 30));
		  osDelay(1);
		  if (motorInfo[k][4] == 1) {
			  	// setMotorRPM(Bus1, M3508, k+1, -1*motorInfo[k][2], test);
		  } else {
			  // setMotorRPM(Bus1, M3508, k+1, motorInfo[k][2], test);
		  }
	  }
	  // setMotorRPM(Bus1, GM6020, 6, 100, test2);
	  osDelay(1);
	  // setMotorRPM(Bus1, GM6020, 5, getRCfakechannel(4), test2);//getRCfakechannel(4)
	  osDelay(1);
	  //usart_printf("%d\r\n", getRCfakechannel(4));
	  /*
	  set_speed_cybergear(&mi_motor[0], (float)((motorInfo[0][2])/200));
	  osDelay(1);
	  set_speed_cybergear(&mi_motor[1], (float)((motorInfo[1][2])/200));
	  osDelay(1);
	  set_speed_cybergear(&mi_motor[2], (float)((motorInfo[2][2])/200));
	  osDelay(1);
	  set_speed_cybergear(&mi_motor[3], (float)((motorInfo[3][2])/200));
	  osDelay(1);
	  */
	  // uint16_t tempor = getRotorPosition(Bus1, GM6020, 1);
	  // usart_printf("%d\r\n", getRotorPosition(Bus1, GM6020, 1));
	  // setMotorRPM(Bus1, GM6020, 0, 10, test2);
	  if (getRCfakechannel(5) == 2) {
		  fondlerAutoReverse (fondlerVars, 1, 1, -1, test);
		  setMotorRPM(Bus1, M2006, 1, 6000, test);
	  } else {
		  fondlerAutoReverse (fondlerVars, 0, 1, -1, test);
		  setMotorRPM(Bus1, M2006, 1, 0, test);
	  }

	  // setMotorRPM(Bus1, M2006, 1, 6000, test);
		osDelay(1);
  }
  /* USER CODE END 5 */
}

void Error_Handler(void)
{
  __disable_irq();
  while (1)
  {
  }
}
